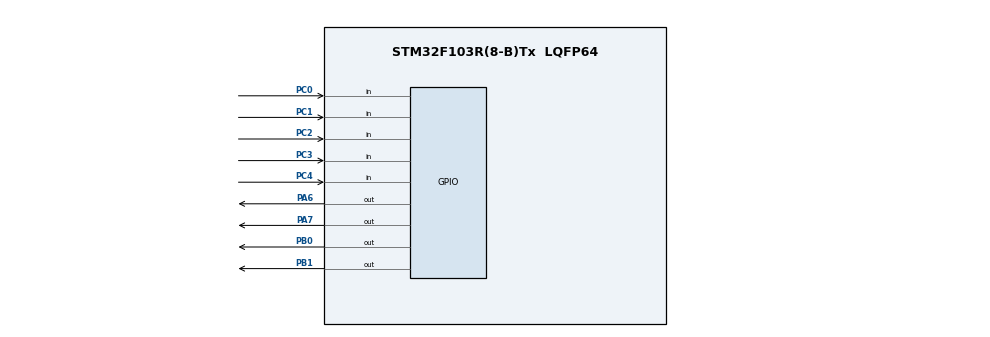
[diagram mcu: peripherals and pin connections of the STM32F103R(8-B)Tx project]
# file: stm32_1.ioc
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Mcu.Family=STM32F1
Mcu.Name=STM32F103R(8-B)Tx
Mcu.Package=LQFP64
NVIC.PriorityGroup=NVIC_PRIORITYGROUP_4
PA6.Signal=GPIO_Output
PA7.Signal=GPIO_Output
PB0.Signal=GPIO_Output
PB1.Signal=GPIO_Output
PC0.Signal=GPIO_Input
PC1.Signal=GPIO_Input
PC2.Signal=GPIO_Input
PC3.Signal=GPIO_Input
PC4.Signal=GPIO_Input
ProjectManager.HeapSize=0x200
ProjectManager.StackSize=0x400
ProjectManager.TargetToolchain=MDK-ARM V5
RCC.APB1Freq_Value=8000000
RCC.APB2Freq_Value=8000000
VP_SYS_VS_ND.Mode=No_Debug
board=custom

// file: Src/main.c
/* USER CODE BEGIN Header */
/**
  ******************************************************************************
  * @file           : main.c
  * @brief          : Main program body
  ******************************************************************************
  * @attention
  *
  * <h2><center>&copy; Copyright (c) 2020 STMicroelectronics.
  * All rights reserved.</center></h2>
  *
  * This software component is licensed by ST under BSD 3-Clause license,
  * the "License"; You may not use this file except in compliance with the
  * License. You may obtain a copy of the License at:
  *                        opensource.org/licenses/BSD-3-Clause
  *
  ******************************************************************************
  */
/* USER CODE END Header */

#include "main.h"

void SystemClock_Config(void);
static void MX_GPIO_Init(void);
void stop(void);
void go_straight(void);
void turn_right(void);
void turn_left(void);
void go_behind(void);

int main(void)
{

  /* MCU Configuration--------------------------------------------------------*/

  /* Reset of all peripherals, Initializes the Flash interface and the Systick. */
  HAL_Init();

  /* Configure the system clock */
  SystemClock_Config();

  /* Initialize all configured peripherals */
  MX_GPIO_Init();

	HAL_Delay(500);
	while(HAL_GPIO_ReadPin(GPIOC, GPIO_PIN_1)){};
	HAL_Delay(500);

  /* Infinite loop */
  /* USER CODE BEGIN WHILE */
  while (1)
  {
		go_straight();
//
//		HAL_Delay(2000);
//		turn_right();

		if(HAL_GPIO_ReadPin(GPIOC, GPIO_PIN_0))
		{
				turn_right();
				while(HAL_GPIO_ReadPin(GPIOC, GPIO_PIN_1))
				{
					go_straight();
				}
				go_behind();
				HAL_Delay(200);
		}else{
			if(HAL_GPIO_ReadPin(GPIOC, GPIO_PIN_1))
			{
				go_straight();
			}else{
				turn_left();
			}
		}

    /* USER CODE END WHILE */

  }
}

void stop(void)
{
	HAL_GPIO_WritePin(GPIOA, GPIO_PIN_6, GPIO_PIN_RESET);
	HAL_GPIO_WritePin(GPIOB, GPIO_PIN_1, GPIO_PIN_RESET);
	HAL_GPIO_WritePin(GPIOA, GPIO_PIN_7, GPIO_PIN_RESET);
	HAL_GPIO_WritePin(GPIOB, GPIO_PIN_0, GPIO_PIN_RESET);
}

void go_straight(void)
{
	HAL_GPIO_WritePin(GPIOA, GPIO_PIN_6, GPIO_PIN_RESET);
	HAL_GPIO_WritePin(GPIOB, GPIO_PIN_1, GPIO_PIN_RESET);
	HAL_GPIO_WritePin(GPIOA, GPIO_PIN_7, GPIO_PIN_SET);
	HAL_GPIO_WritePin(GPIOB, GPIO_PIN_0, GPIO_PIN_RESET);

	HAL_Delay(5);

	HAL_GPIO_WritePin(GPIOA, GPIO_PIN_6, GPIO_PIN_RESET);
	HAL_GPIO_WritePin(GPIOB, GPIO_PIN_1, GPIO_PIN_RESET);
	HAL_GPIO_WritePin(GPIOA, GPIO_PIN_7, GPIO_PIN_SET);
	HAL_GPIO_WritePin(GPIOB, GPIO_PIN_0, GPIO_PIN_SET);

	HAL_Delay(50);
}

void go_behind(void)
{
	HAL_GPIO_WritePin(GPIOA, GPIO_PIN_6, GPIO_PIN_RESET);
	HAL_GPIO_WritePin(GPIOB, GPIO_PIN_1, GPIO_PIN_SET);
	HAL_GPIO_WritePin(GPIOA, GPIO_PIN_7, GPIO_PIN_RESET);
	HAL_GPIO_WritePin(GPIOB, GPIO_PIN_0, GPIO_PIN_RESET);

	HAL_Delay(5);

	HAL_GPIO_WritePin(GPIOA, GPIO_PIN_6, GPIO_PIN_SET);
	HAL_GPIO_WritePin(GPIOB, GPIO_PIN_1, GPIO_PIN_SET);
	HAL_GPIO_WritePin(GPIOA, GPIO_PIN_7, GPIO_PIN_RESET);
	HAL_GPIO_WritePin(GPIOB, GPIO_PIN_0, GPIO_PIN_RESET);

	HAL_Delay(50);
}

void turn_right(void)
{
	HAL_GPIO_WritePin(GPIOA, GPIO_PIN_6, GPIO_PIN_RESET);
	HAL_GPIO_WritePin(GPIOB, GPIO_PIN_1, GPIO_PIN_RESET);
	HAL_GPIO_WritePin(GPIOA, GPIO_PIN_7, GPIO_PIN_RESET);
	HAL_GPIO_WritePin(GPIOB, GPIO_PIN_0, GPIO_PIN_SET);

	HAL_Delay(400);

	HAL_GPIO_WritePin(GPIOA, GPIO_PIN_6, GPIO_PIN_SET);
	HAL_GPIO_WritePin(GPIOB, GPIO_PIN_1, GPIO_PIN_RESET);
	HAL_GPIO_WritePin(GPIOA, GPIO_PIN_7, GPIO_PIN_RESET);
	HAL_GPIO_WritePin(GPIOB, GPIO_PIN_0, GPIO_PIN_SET);

	HAL_Delay(250);

	stop();
	HAL_Delay(100);
}

void turn_left(void)
{
	HAL_GPIO_WritePin(GPIOA, GPIO_PIN_6, GPIO_PIN_RESET);
	HAL_GPIO_WritePin(GPIOB, GPIO_PIN_1, GPIO_PIN_SET);
	HAL_GPIO_WritePin(GPIOA, GPIO_PIN_7, GPIO_PIN_SET);
	HAL_GPIO_WritePin(GPIOB, GPIO_PIN_0, GPIO_PIN_RESET);

	HAL_Delay(600);

	stop();
	HAL_Delay(100);
}

void SystemClock_Config(void)
{
  RCC_OscInitTypeDef RCC_OscInitStruct = {0};
  RCC_ClkInitTypeDef RCC_ClkInitStruct = {0};

  /** Initializes the CPU, AHB and APB busses clocks
  */
  RCC_OscInitStruct.OscillatorType = RCC_OSCILLATORTYPE_HSI;
  RCC_OscInitStruct.HSIState = RCC_HSI_ON;
  RCC_OscInitStruct.HSICalibrationValue = RCC_HSICALIBRATION_DEFAULT;
  RCC_OscInitStruct.PLL.PLLState = RCC_PLL_NONE;
  if (HAL_RCC_OscConfig(&RCC_OscInitStruct) != HAL_OK)
  {
    Error_Handler();
  }
  /** Initializes the CPU, AHB and APB busses clocks
  */
  RCC_ClkInitStruct.ClockType = RCC_CLOCKTYPE_HCLK|RCC_CLOCKTYPE_SYSCLK
                              |RCC_CLOCKTYPE_PCLK1|RCC_CLOCKTYPE_PCLK2;
  RCC_ClkInitStruct.SYSCLKSource = RCC_SYSCLKSOURCE_HSI;
  RCC_ClkInitStruct.AHBCLKDivider = RCC_SYSCLK_DIV1;
  RCC_ClkInitStruct.APB1CLKDivider = RCC_HCLK_DIV1;
  RCC_ClkInitStruct.APB2CLKDivider = RCC_HCLK_DIV1;

  if (HAL_RCC_ClockConfig(&RCC_ClkInitStruct, FLASH_LATENCY_0) != HAL_OK)
  {
    Error_Handler();
  }
}

static void MX_GPIO_Init(void)
{
  GPIO_InitTypeDef GPIO_InitStruct = {0};

  /* GPIO Ports Clock Enable */
  __HAL_RCC_GPIOC_CLK_ENABLE();
  __HAL_RCC_GPIOA_CLK_ENABLE();
  __HAL_RCC_GPIOB_CLK_ENABLE();

  /*Configure GPIO pin Output Level */
  HAL_GPIO_WritePin(GPIOA, GPIO_PIN_6|GPIO_PIN_7, GPIO_PIN_RESET);

  /*Configure GPIO pin Output Level */
  HAL_GPIO_WritePin(GPIOB, GPIO_PIN_0|GPIO_PIN_1, GPIO_PIN_RESET);

  /*Configure GPIO pins : PC0 PC1 PC2 PC3
                           PC4 */
  GPIO_InitStruct.Pin = GPIO_PIN_0|GPIO_PIN_1|GPIO_PIN_2|GPIO_PIN_3
                          |GPIO_PIN_4;
  GPIO_InitStruct.Mode = GPIO_MODE_INPUT;
  GPIO_InitStruct.Pull = GPIO_NOPULL;
  HAL_GPIO_Init(GPIOC, &GPIO_InitStruct);

  /*Configure GPIO pins : PA6 PA7 */
  GPIO_InitStruct.Pin = GPIO_PIN_6|GPIO_PIN_7;
  GPIO_InitStruct.Mode = GPIO_MODE_OUTPUT_PP;
  GPIO_InitStruct.Pull = GPIO_NOPULL;
  GPIO_InitStruct.Speed = GPIO_SPEED_FREQ_LOW;
  HAL_GPIO_Init(GPIOA, &GPIO_InitStruct);

  /*Configure GPIO pins : PB0 PB1 */
  GPIO_InitStruct.Pin = GPIO_PIN_0|GPIO_PIN_1;
  GPIO_InitStruct.Mode = GPIO_MODE_OUTPUT_PP;
  GPIO_InitStruct.Pull = GPIO_NOPULL;
  GPIO_InitStruct.Speed = GPIO_SPEED_FREQ_LOW;
  HAL_GPIO_Init(GPIOB, &GPIO_InitStruct);

}

void Error_Handler(void)
{
}

/************************ (C) COPYRIGHT STMicroelectronics *****END OF FILE****/
